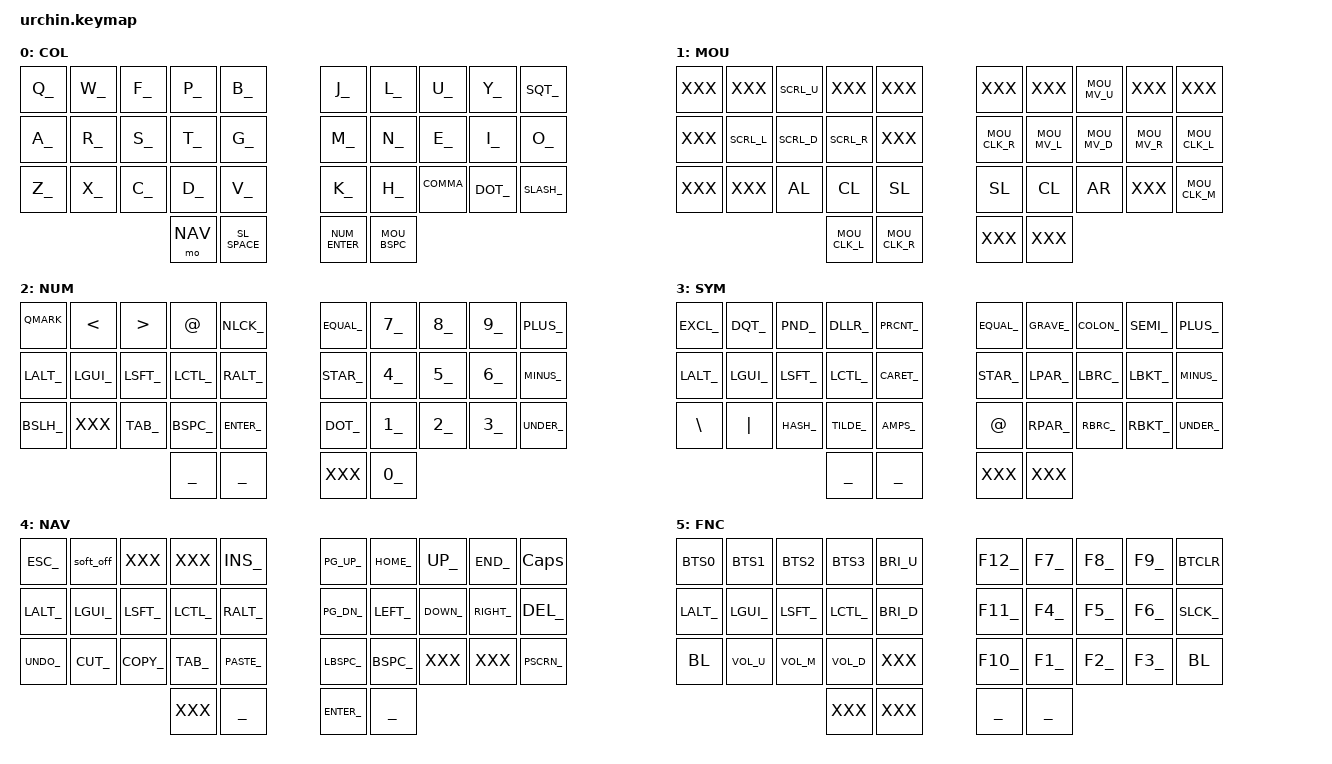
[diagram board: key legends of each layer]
#include "core.h"

ZMK_LAYER(COL,
// ╭───────────┬───────────┬───────────┬────────────┬────────────╮ ╭───────────┬─────────────┬─────────────┬────────────┬────────────╮
     _Q_         _W_         _F_         _P_          _B_            _J_         _L_           _U_           _Y_          _SQT_
// ├───────────┼───────────┼───────────┼────────────┼────────────┤ ├───────────┼─────────────┼─────────────┼────────────┼────────────┤
     _A_         _R_         _S_         _T_          _G_            _M_         _N_           _E_           _I_          _O_
// ├───────────┼───────────┼───────────┼────────────┼────────────┤ ├───────────┼─────────────┼─────────────┼────────────┼────────────┤
     _Z_         _X_         _C_         _D_          _V_            _K_         _H_           _COMMA_       _DOT_        _SLASH_
// ╰───────────┴───────────┴───────────┼────────────┼────────────┤ ├───────────┼─────────────┼─────────────┴────────────┴────────────╯
                                         &mo NAV      SL_SPACE       NUM_ENTER   MOU_BSPC
//                                     ╰────────────┴────────────╯ ╰───────────┴─────────────╯
)

ZMK_LAYER(MOU,
// ╭───────────┬───────────┬───────────┬────────────┬────────────╮ ╭───────────┬─────────────┬─────────────┬────────────┬────────────╮
     XXX         XXX         &SCRL_U     XXX          XXX            XXX         XXX           &MOU_MV_U     XXX          XXX
// ├───────────┼───────────┼───────────┼────────────┼────────────┤ ├───────────┼─────────────┼─────────────┼────────────┼────────────┤
     XXX         &SCRL_L     &SCRL_D     &SCRL_R      XXX            &MOU_CLK_R  &MOU_MV_L     &MOU_MV_D     &MOU_MV_R    &MOU_CLK_L
// ├───────────┼───────────┼───────────┼────────────┼────────────┤ ├───────────┼─────────────┼─────────────┼────────────┼────────────┤
     XXX         XXX         &kp AL      &kp CL       &kp SL         &kp SL      &kp CL        &kp AR        XXX          &MOU_CLK_M
// ╰───────────┴───────────┴───────────┼────────────┼────────────┤ ├───────────┼─────────────┼─────────────┴────────────┴────────────╯
                                         &MOU_CLK_L   &MOU_CLK_R     XXX         XXX
//                                     ╰────────────┴────────────╯ ╰───────────┴─────────────╯
)

ZMK_LAYER(NUM,
// ╭───────────┬───────────┬───────────┬────────────┬────────────╮ ╭───────────┬─────────────┬─────────────┬────────────┬────────────╮
     _QMARK_     &kp LT      &kp GT      &kp AT       _NLCK_         _EQUAL_     _7_           _8_           _9_          _PLUS_
// ├───────────┼───────────┼───────────┼────────────┼────────────┤ ├───────────┼─────────────┼─────────────┼────────────┼────────────┤
     _LALT_      _LGUI_      _LSFT_      _LCTL_       _RALT_         _STAR_      _4_           _5_           _6_          _MINUS_
// ├───────────┼───────────┼───────────┼────────────┼────────────┤ ├───────────┼─────────────┼─────────────┼────────────┼────────────┤
     _BSLH_      XXX         _TAB_       _BSPC_       _ENTER_        _DOT_       _1_           _2_           _3_          _UNDER_
// ╰───────────┴───────────┴───────────┼────────────┼────────────┤ ├───────────┼─────────────┼─────────────┴────────────┴────────────╯
                                         ___          ___            XXX         _0_
//                                     ╰────────────┴────────────╯ ╰───────────┴─────────────╯
)

ZMK_LAYER(SYM,
// ╭───────────┬───────────┬───────────┬────────────┬────────────╮ ╭───────────┬─────────────┬─────────────┬────────────┬────────────╮
     _EXCL_      _DQT_       _PND_       _DLLR_       _PRCNT_        _EQUAL_     _GRAVE_       _COLON_       _SEMI_       _PLUS_
// ├───────────┼───────────┼───────────┼────────────┼────────────┤ ├───────────┼─────────────┼─────────────┼────────────┼────────────┤
     _LALT_      _LGUI_      _LSFT_      _LCTL_       _CARET_        _STAR_      _LPAR_        _LBRC_        _LBKT_       _MINUS_
// ├───────────┼───────────┼───────────┼────────────┼────────────┤ ├───────────┼─────────────┼─────────────┼────────────┼────────────┤
     &kp BSLH    &kp PIPE    _HASH_      _TILDE_      _AMPS_         &kp AT      _RPAR_        _RBRC_        _RBKT_       _UNDER_
// ╰───────────┴───────────┴───────────┼────────────┼────────────┤ ├───────────┼─────────────┼─────────────┴────────────┴────────────╯
                                         ___          ___            XXX         XXX
//                                     ╰────────────┴────────────╯ ╰───────────┴─────────────╯
)

ZMK_LAYER(NAV,
// ╭───────────┬───────────┬───────────┬────────────┬────────────╮ ╭───────────┬─────────────┬─────────────┬────────────┬────────────╮
     _ESC_       &soft_off   XXX         XXX          _INS_          _PG_UP_     _HOME_        _UP_          _END_        &kp CAPS
// ├───────────┼───────────┼───────────┼────────────┼────────────┤ ├───────────┼─────────────┼─────────────┼────────────┼────────────┤
     _LALT_      _LGUI_      _LSFT_      _LCTL_       _RALT_         _PG_DN_     _LEFT_        _DOWN_        _RIGHT_      _DEL_
// ├───────────┼───────────┼───────────┼────────────┼────────────┤ ├───────────┼─────────────┼─────────────┼────────────┼────────────┤
     _UNDO_      _CUT_       _COPY_      _TAB_        _PASTE_        _LBSPC_     _BSPC_        XXX           XXX          _PSCRN_
// ╰───────────┴───────────┴───────────┼────────────┼────────────┤ ├───────────┼─────────────┼─────────────┴────────────┴────────────╯
                                         XXX          ___            _ENTER_     ___
//                                     ╰────────────┴────────────╯ ╰───────────┴─────────────╯
)

ZMK_LAYER(FNC,
// ╭───────────┬───────────┬───────────┬────────────┬────────────╮ ╭───────────┬─────────────┬─────────────┬────────────┬────────────╮
     BTS0        BTS1        BTS2        BTS3         BRI_U          _F12_       _F7_          _F8_          _F9_         BTCLR
// ├───────────┼───────────┼───────────┼────────────┼────────────┤ ├───────────┼─────────────┼─────────────┼────────────┼────────────┤
     _LALT_      _LGUI_      _LSFT_      _LCTL_       BRI_D          _F11_       _F4_          _F5_          _F6_         _SLCK_
// ├───────────┼───────────┼───────────┼────────────┼────────────┤ ├───────────┼─────────────┼─────────────┼────────────┼────────────┤
     BL          VOL_U       VOL_M       VOL_D        XXX            _F10_       _F1_          _F2_          _F3_         BL
// ╰───────────┴───────────┴───────────┼────────────┼────────────┤ ├───────────┼─────────────┼─────────────┴────────────┴────────────╯
                                         XXX          XXX            ___         ___
//                                     ╰────────────┴────────────╯ ╰───────────┴─────────────╯
)
